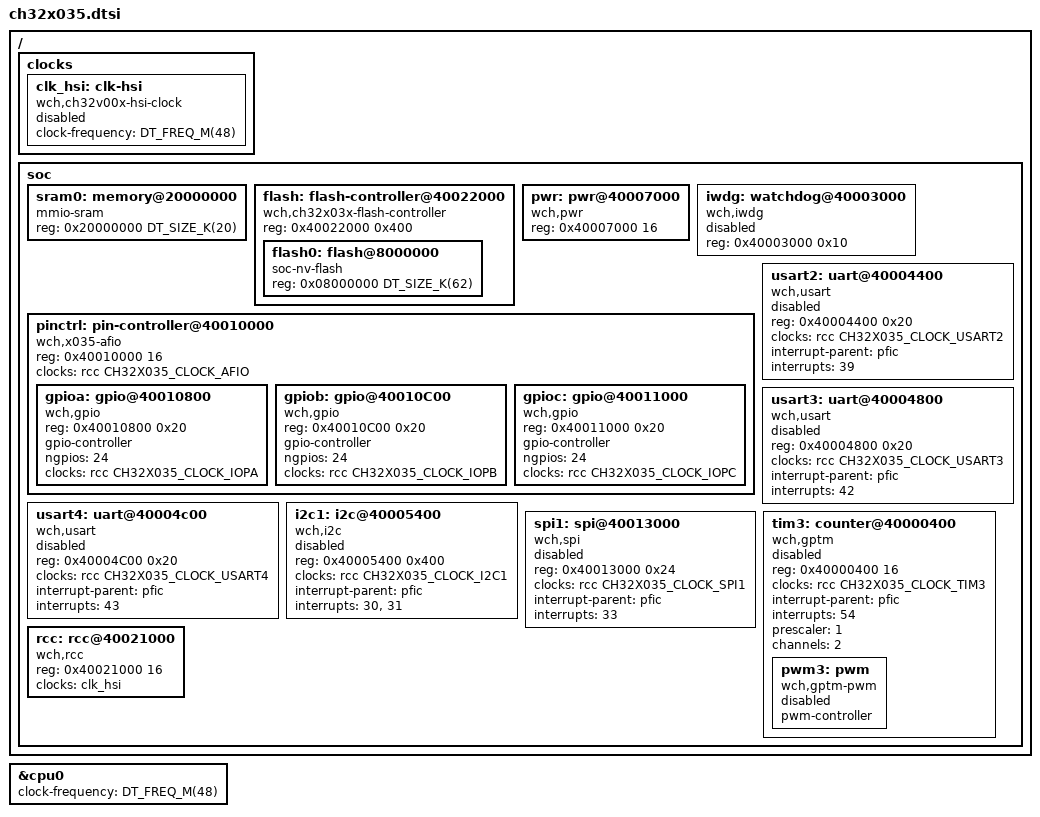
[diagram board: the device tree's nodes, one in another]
/*
 * Copyright (c) 2025 TiaC Systems
 * SPDX-License-Identifier: Apache-2.0
 */

#include <freq.h>
#include <mem.h>
#include <wch/qingke-v4c.dtsi>
#include <zephyr/dt-bindings/gpio/gpio.h>
#include <zephyr/dt-bindings/i2c/i2c.h>
#include <zephyr/dt-bindings/clock/ch32x035-clocks.h>

/ {
	clocks {
		clk_hsi: clk-hsi {
			#clock-cells = <0>;
			compatible = "wch,ch32v00x-hsi-clock";
			clock-frequency = <DT_FREQ_M(48)>;
			status = "disabled";
		};
	};

	soc {
		sram0: memory@20000000 {
			compatible = "mmio-sram";
			reg = <0x20000000 DT_SIZE_K(20)>;
		};

		flash: flash-controller@40022000 {
			compatible = "wch,ch32x03x-flash-controller";
			reg = <0x40022000 0x400>;
			#address-cells = <1>;
			#size-cells = <1>;

			flash0: flash@8000000 {
				compatible = "soc-nv-flash";
				reg = <0x08000000 DT_SIZE_K(62)>;
			};
		};

		pwr: pwr@40007000 {
			compatible = "wch,pwr";
			reg = <0x40007000 16>;
		};

		iwdg: watchdog@40003000 {
			compatible = "wch,iwdg";
			reg = <0x40003000 0x10>;
			status = "disabled";
		};

		pinctrl: pin-controller@40010000 {
			compatible = "wch,x035-afio";
			reg = <0x40010000 16>;
			#address-cells = <1>;
			#size-cells = <1>;
			clocks = <&rcc CH32X035_CLOCK_AFIO>;

			gpioa: gpio@40010800 {
				compatible = "wch,gpio";
				reg = <0x40010800 0x20>;
				gpio-controller;
				#gpio-cells = <2>;
				ngpios = <24>;
				clocks = <&rcc CH32X035_CLOCK_IOPA>;
			};

			gpiob: gpio@40010C00 {
				compatible = "wch,gpio";
				reg = <0x40010C00 0x20>;
				gpio-controller;
				#gpio-cells = <2>;
				ngpios = <24>;
				clocks = <&rcc CH32X035_CLOCK_IOPB>;
			};

			gpioc: gpio@40011000 {
				compatible = "wch,gpio";
				reg = <0x40011000 0x20>;
				gpio-controller;
				#gpio-cells = <2>;
				ngpios = <24>;
				clocks = <&rcc CH32X035_CLOCK_IOPC>;
			};
		};

		usart2: uart@40004400 {
			compatible = "wch,usart";
			reg = <0x40004400 0x20>;
			clocks = <&rcc CH32X035_CLOCK_USART2>;
			interrupt-parent = <&pfic>;
			interrupts = <39>;
			status = "disabled";
		};

		usart3: uart@40004800 {
			compatible = "wch,usart";
			reg = <0x40004800 0x20>;
			clocks = <&rcc CH32X035_CLOCK_USART3>;
			interrupt-parent = <&pfic>;
			interrupts = <42>;
			status = "disabled";
		};

		usart4: uart@40004c00 {
			compatible = "wch,usart";
			reg = <0x40004C00 0x20>;
			clocks = <&rcc CH32X035_CLOCK_USART4>;
			interrupt-parent = <&pfic>;
			interrupts = <43>;
			status = "disabled";
		};

		i2c1: i2c@40005400 {
			compatible = "wch,i2c";
			reg = <0x40005400 0x400>;
			clocks = <&rcc CH32X035_CLOCK_I2C1>;
			interrupt-parent = <&pfic>;
			interrupts = <30>, <31>;
			status = "disabled";
			#address-cells = <1>;
			#size-cells = <0>;
		};

		spi1: spi@40013000 {
			compatible = "wch,spi";
			reg = <0x40013000 0x24>;
			clocks = <&rcc CH32X035_CLOCK_SPI1>;
			interrupt-parent = <&pfic>;
			interrupts = <33>;
			status = "disabled";
			#address-cells = <1>;
			#size-cells = <0>;
		};

		tim3: counter@40000400 {
			compatible = "wch,gptm";
			reg = <0x40000400 16>;
			clocks = <&rcc CH32X035_CLOCK_TIM3>;
			interrupt-parent = <&pfic>;
			interrupts = <54>;
			interrupt-names = "global";
			status = "disabled";
			prescaler = <1>;
			channels = <2>;

			pwm3: pwm {
				compatible = "wch,gptm-pwm";
				pwm-controller;
				#pwm-cells = <3>;
				status = "disabled";
			};
		};

		rcc: rcc@40021000 {
			compatible = "wch,rcc";
			reg = <0x40021000 16>;
			#clock-cells = <1>;
			clocks = <&clk_hsi>;
		};
	};
};

&cpu0 {
	clock-frequency = <DT_FREQ_M(48)>;
};
